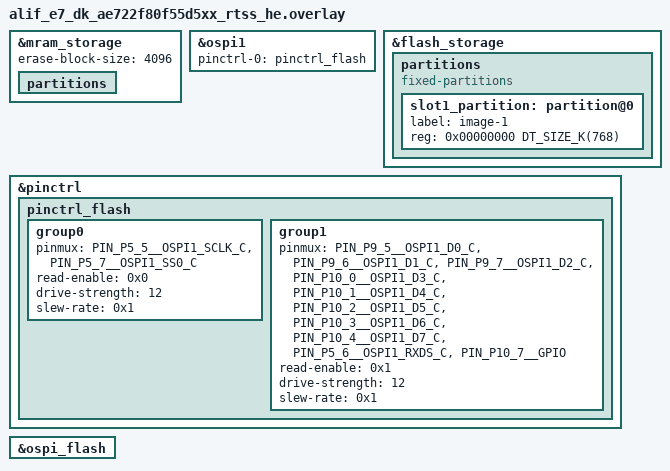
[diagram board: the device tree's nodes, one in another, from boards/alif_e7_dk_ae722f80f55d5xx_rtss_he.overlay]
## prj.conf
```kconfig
# Enable MCUmgr and dependencies.
CONFIG_NET_BUF=y
CONFIG_ZCBOR=y
CONFIG_CRC=y
CONFIG_MCUMGR=y
CONFIG_STREAM_FLASH=y
CONFIG_FLASH_MAP=y

# Some command handlers require a large stack.
CONFIG_SYSTEM_WORKQUEUE_STACK_SIZE=2304
CONFIG_MAIN_STACK_SIZE=2048

# Ensure an MCUboot-compatible binary is generated.
CONFIG_BOOTLOADER_MCUBOOT=y

# Enable flash operations.
CONFIG_FLASH=y

# Required by the `taskstat` command.
CONFIG_THREAD_MONITOR=y

# Support for taskstat command
CONFIG_MCUMGR_GRP_OS_TASKSTAT=y

# Enable statistics and statistic names.
CONFIG_STATS=y
CONFIG_STATS_NAMES=y

# Enable most core commands.
CONFIG_FLASH=y
CONFIG_IMG_MANAGER=y
CONFIG_MCUMGR_GRP_IMG=y
CONFIG_MCUMGR_GRP_OS=y
CONFIG_MCUMGR_GRP_STAT=y

# Enable logging
CONFIG_LOG=y
CONFIG_MCUBOOT_UTIL_LOG_LEVEL_WRN=y

# Disable debug logging
CONFIG_LOG_MAX_LEVEL=3

# Flash stuff
#Enable OSPI Flash
CONFIG_OSPI_FLASH_IS25WX=y
CONFIG_OSPI=y
CONFIG_USE_ALIF_HAL_OSPI=y
```

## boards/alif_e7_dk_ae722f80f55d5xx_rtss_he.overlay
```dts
////////////////////////////////////////////////////////////////////////////////
#if 1

&mram_storage {
	erase-block-size = <4096>;
	partitions {
		/delete-node/ partition@D0000;
	};
};

&ospi1 {
	status = "okay";
	pinctrl-0 = <&pinctrl_flash>;
};

&flash_storage {
	// write-block-size = <1>;
	partitions {
		compatible = "fixed-partitions";
		#address-cells = <1>;
		#size-cells = <1>;

		slot1_partition: partition@0 {
			label = "image-1";
			reg = <0x00000000 DT_SIZE_K(768)>;
		};
	};
};

&pinctrl {
	pinctrl_flash:pinctrl_flash {
		group0 {
			pinmux = <PIN_P5_5__OSPI1_SCLK_C>,
				 <PIN_P5_7__OSPI1_SS0_C>;
			read-enable = <0x0>;
			drive-strength = <12>;
			slew-rate = <0x1>;
		};
		group1 {
			pinmux = <PIN_P9_5__OSPI1_D0_C>,
				 <PIN_P9_6__OSPI1_D1_C>,
				 <PIN_P9_7__OSPI1_D2_C>,
				 <PIN_P10_0__OSPI1_D3_C>,
				 <PIN_P10_1__OSPI1_D4_C>,
				 <PIN_P10_2__OSPI1_D5_C>,
				 <PIN_P10_3__OSPI1_D6_C>,
				 <PIN_P10_4__OSPI1_D7_C>,
				 <PIN_P5_6__OSPI1_RXDS_C>,    /* RxDS : Func */
				 <PIN_P10_7__GPIO>;           /* RxDS : Pin */
			read-enable = <0x1>;
			drive-strength = <12>;
			slew-rate = <0x1>;
		};
	};
};


&ospi_flash {
	// write-block-size = <1>;
	status = "okay";
};
#endif
```

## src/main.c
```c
/*
 * Copyright (c) 2012-2014 Wind River Systems, Inc.
 * Copyright (c) 2020 Prevas A/S
 *
 * SPDX-License-Identifier: Apache-2.0
 */

#include <zephyr/kernel.h>
#include <zephyr/stats/stats.h>
#include <zephyr/usb/usb_device.h>

#ifdef CONFIG_MCUMGR_GRP_FS
#include <zephyr/device.h>
#include <zephyr/fs/fs.h>
#include <zephyr/fs/littlefs.h>
#endif
#ifdef CONFIG_MCUMGR_GRP_STAT
#include <zephyr/mgmt/mcumgr/grp/stat_mgmt/stat_mgmt.h>
#endif

#define LOG_LEVEL LOG_LEVEL_DBG
#include <zephyr/logging/log.h>
LOG_MODULE_REGISTER(smp_sample);

#include "common.h"

#define STORAGE_PARTITION_LABEL	storage_partition
#define STORAGE_PARTITION_ID	FIXED_PARTITION_ID(STORAGE_PARTITION_LABEL)

/* Define an example stats group; approximates seconds since boot. */
STATS_SECT_START(smp_svr_stats)
STATS_SECT_ENTRY(ticks)
STATS_SECT_END;

/* Assign a name to the `ticks` stat. */
STATS_NAME_START(smp_svr_stats)
STATS_NAME(smp_svr_stats, ticks)
STATS_NAME_END(smp_svr_stats);

/* Define an instance of the stats group. */
STATS_SECT_DECL(smp_svr_stats) smp_svr_stats;

#ifdef CONFIG_MCUMGR_GRP_FS
FS_LITTLEFS_DECLARE_DEFAULT_CONFIG(cstorage);
static struct fs_mount_t littlefs_mnt = {
	.type = FS_LITTLEFS,
	.fs_data = &cstorage,
	.storage_dev = (void *)STORAGE_PARTITION_ID,
	.mnt_point = "/lfs1"
};
#endif

int main(void)
{
	int rc = STATS_INIT_AND_REG(smp_svr_stats, STATS_SIZE_32,
				    "smp_svr_stats");

	if (rc < 0) {
		LOG_ERR("Error  initializing stats system [%d]", rc);
	}

	/* Register the built-in mcumgr command handlers. */
#ifdef CONFIG_MCUMGR_GRP_FS
	rc = fs_mount(&littlefs_mnt);
	if (rc < 0) {
		LOG_ERR("Error mounting littlefs [%d]", rc);
	}
#endif

#ifdef CONFIG_MCUMGR_TRANSPORT_BT
	start_smp_bluetooth_adverts();
#endif

	if (IS_ENABLED(CONFIG_USB_DEVICE_STACK)) {
		rc = usb_enable(NULL);

		/* Ignore EALREADY error as USB CDC is likely already initialised */
		if (rc != 0 && rc != -EALREADY) {
			LOG_ERR("Failed to enable USB");
			return 0;
		}
	}
	/* using __TIME__ ensure that a new binary will be built on every
	 * compile which is convenient when testing firmware upgrade.
	 */
	LOG_INF("build time: " __DATE__ " " __TIME__);

	/* The system work queue handles all incoming mcumgr requests.  Let the
	 * main thread idle while the mcumgr server runs.
	 */
	while (1) {
		k_sleep(K_MSEC(1000));
		STATS_INC(smp_svr_stats, ticks);
	}
	return 0;
}
```
